AUTOSAR XML (schema 00048)
package /HuaweiMDC/FunctionalSoftware/Location/Execution
  executable fusion_location_execute
    root sw component prototype fusion_location_root_swc: application-type=fusion_location_base
package /HuaweiMDC/FunctionalSoftware/Location/SwComponent
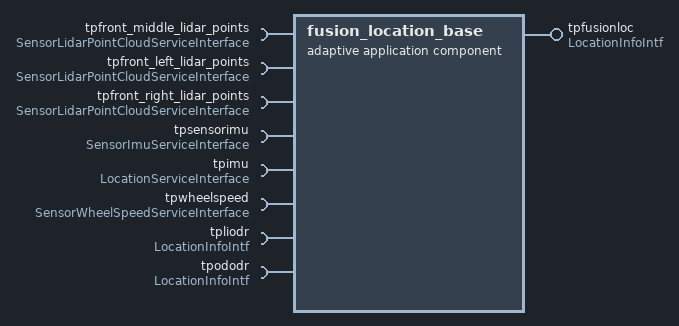
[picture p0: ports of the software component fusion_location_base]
  adaptive application sw component type fusion_location_base
    provide port tpfusionloc: provided-interface=LocationInfoIntf
    8 x require port:
      tpfront_middle_lidar_points: required-interface=SensorLidarPointCloudServiceInterface
      tpfront_left_lidar_points: required-interface=SensorLidarPointCloudServiceInterface
      tpfront_right_lidar_points: required-interface=SensorLidarPointCloudServiceInterface
      tpsensorimu: required-interface=SensorImuServiceInterface
      tpimu: required-interface=LocationServiceInterface
      tpwheelspeed: required-interface=SensorWheelSpeedServiceInterface
      tpliodr: required-interface=LocationInfoIntf
      tpododr: required-interface=LocationInfoIntf
